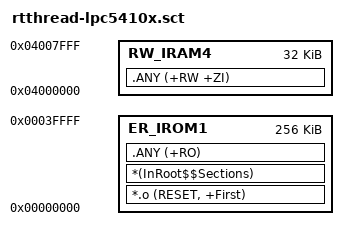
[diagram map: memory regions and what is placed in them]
; *************************************************************
; *** Scatter-Loading Description File generated by uVision ***
; *************************************************************

LR_IROM1 0x00000000 0x00040000  {    ; load region size_region
  ER_IROM1 0x00000000 0x00040000  {  ; load address = execution address
   *.o (RESET, +First)
   *(InRoot$$Sections)
   .ANY (+RO)
  }
  
;  RW_IRAM1 0x20000000 0x00010000  {  ; RW data
;   .ANY (+RW +ZI)
;  }
;  RW_IRAM2 0x20010000 0x00010000  {  ; RW data
;   .ANY (+RW +ZI)
;  }
;  RW_IRAM3 0x20027000 0x00001000  {  ; RW data
;   .ANY (+RW +ZI)
;  }
  RW_IRAM4 0x04000000 0x00008000  {  ; RW data
   .ANY (+RW +ZI)
  }
; test only  
;  RW_IRAM5 0x04000000 0x00200000  {  ; RW data
;   .ANY (+RW +ZI)
;  }
}

